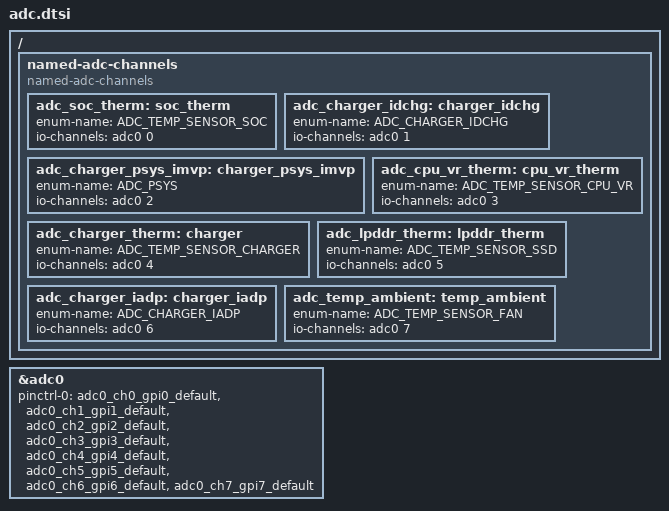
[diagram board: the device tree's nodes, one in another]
/* Copyright 2025 The ChromiumOS Authors
 * Use of this source code is governed by a BSD-style license that can be
 * found in the LICENSE file.
 */

/ {
	named-adc-channels {
		compatible = "named-adc-channels";

		adc_soc_therm: soc_therm {
			enum-name = "ADC_TEMP_SENSOR_SOC";
			io-channels = <&adc0 0>;
		};
		adc_charger_idchg: charger_idchg {
			enum-name = "ADC_CHARGER_IDCHG";
			io-channels = <&adc0 1>;
		};
		adc_charger_psys_imvp: charger_psys_imvp {
			enum-name = "ADC_PSYS";
			io-channels = <&adc0 2>;
		};
		adc_cpu_vr_therm: cpu_vr_therm {
			enum-name = "ADC_TEMP_SENSOR_CPU_VR";
			io-channels = <&adc0 3>;
		};
		adc_charger_therm: charger {
			enum-name = "ADC_TEMP_SENSOR_CHARGER";
			io-channels = <&adc0 4>;
		};
		adc_lpddr_therm: lpddr_therm {
			enum-name = "ADC_TEMP_SENSOR_SSD";
			io-channels = <&adc0 5>;
		};
		adc_charger_iadp: charger_iadp {
			enum-name = "ADC_CHARGER_IADP";
			io-channels = <&adc0 6>;
		};
		adc_temp_ambient: temp_ambient {
			enum-name = "ADC_TEMP_SENSOR_FAN";
			io-channels = <&adc0 7>;
		};
	};
};

&adc0 {
	status = "okay";
	pinctrl-0 = <&adc0_ch0_gpi0_default
		&adc0_ch1_gpi1_default
		&adc0_ch2_gpi2_default
		&adc0_ch3_gpi3_default
		&adc0_ch4_gpi4_default
		&adc0_ch5_gpi5_default
		&adc0_ch6_gpi6_default
		&adc0_ch7_gpi7_default>;
	pinctrl-names = "default";
};
